# ESP32 register map
Vendor: ESPRESSIF SYSTEMS (SHANGHAI) CO., LTD.; Series: ESP32 Series; File version: 17
CPU: Xtensa LX6 r0p0, little endian, no MPU, FPU, 0 interrupt priority bits
Address unit: 32 bits
Registers are 32-bit, read-write, reset 0x0 unless marked. A register's access mark holds for its fields unless they carry their own. Offsets are from the block's base; [hi:lo] are bit positions; lines under a group give offsets from that group; {n}, {i} and the like mark numbered series; 'fields as' and 'values as' point back to an identical list.

## FLASH_ENCRYPTION — FLASH_ENCRYPTION Peripheral
Base 0x3FF46000
{0x0+4i} BUFFER_{i} (i=0..7) wo
  [7:0] BUFFER — Data buffers for encryption.
0x20 START wo
  [7:0] FLASH_START — Set this bit to start encryption operation on data buffer.
0x24 ADDRESS wo
  [7:0] ADDRESS — The physical address on the off-chip flash must be 8-word boundary aligned.
0x28 DONE ro
  [0] FLASH_DONE — Set this bit when encryption operation is complete.

## FRC_TIMER — FRC_TIMER Peripheral
Base 0x3FF47000
0x00 TIMER_LOAD
  [7:0] VALUE
0x04 TIMER_COUNT
  [7:0] TIMER_COUNT
0x08 TIMER_CTRL
  [8:1] TIMER_PRESCALER
0x0C TIMER_INT
  [0] CLR
0x10 TIMER_ALARM
  [7:0] TIMER_ALARM

## GPIO_SD — Sigma-Delta Modulation
Base 0x3FF44F00
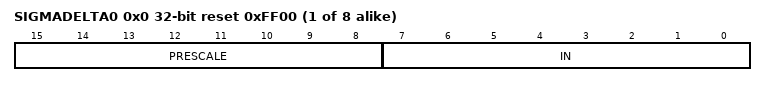
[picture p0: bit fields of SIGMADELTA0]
{0x0+4i} SIGMADELTA{i} (i=0..7) reset 0xFF00
  [15:8] PRESCALE, [7:0] IN
0x20 CLOCK_GATE
  [31] CLK_EN
0x24 SIGMADELTA_MISC
  [31] SPI_SWAP
0x28 VERSION

## HINF — HINF Peripheral
Base 0x3FF4B000
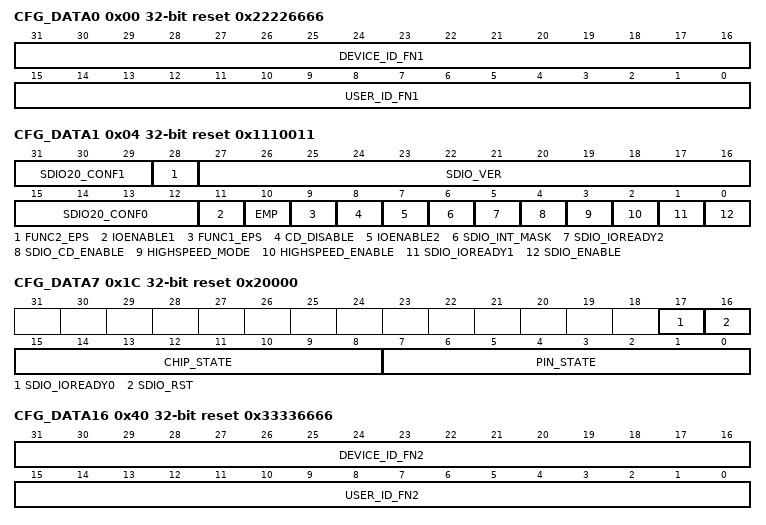
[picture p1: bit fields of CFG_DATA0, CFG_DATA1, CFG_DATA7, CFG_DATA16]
0x00 CFG_DATA0 reset 0x22226666
  [31:16] DEVICE_ID_FN1, [15:0] USER_ID_FN1
0x04 CFG_DATA1 access per field reset 0x1110011
  [31:29] SDIO20_CONF1 rw, [28] FUNC2_EPS ro, [27:16] SDIO_VER rw, [15:12] SDIO20_CONF0 rw, [11] IOENABLE1 ro, [10] EMP ro, [9] FUNC1_EPS ro, [8] CD_DISABLE ro, [7] IOENABLE2 ro, [6] SDIO_INT_MASK rw, [5] SDIO_IOREADY2 rw, [4] SDIO_CD_ENABLE rw, [3] HIGHSPEED_MODE ro, [2] HIGHSPEED_ENABLE rw, [1] SDIO_IOREADY1 rw, [0] SDIO_ENABLE rw
0x1C CFG_DATA7 reset 0x20000
  [17] SDIO_IOREADY0, [16] SDIO_RST, [15:8] CHIP_STATE, [7:0] PIN_STATE
{0x20+4i} CIS_CONF{i} reset 0xFFFFFFFF (i=0..7)
  [31:0] CIS_CONF_W{i}
0x40 CFG_DATA16 reset 0x33336666
  [31:16] DEVICE_ID_FN2, [15:0] USER_ID_FN2
0xFC DATE

## NRX — NRX Peripheral
Base 0x3FF5CC00
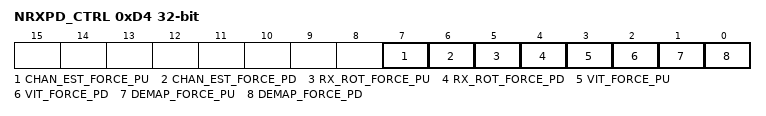
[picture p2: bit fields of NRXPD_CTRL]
0xD4 NRXPD_CTRL — WiFi RX control register
  [7] CHAN_EST_FORCE_PU, [6] CHAN_EST_FORCE_PD, [5] RX_ROT_FORCE_PU, [4] RX_ROT_FORCE_PD, [3] VIT_FORCE_PU, [2] VIT_FORCE_PD, [1] DEMAP_FORCE_PU, [0] DEMAP_FORCE_PD

## PCNT — Pulse Count Controller
Base 0x3FF57000
{0x0+0xC*i} UNIT{i} (i=0..7) group — Cluster UNIT{i}, containing U?_CONF0, U?_CONF1, U?_CONF2
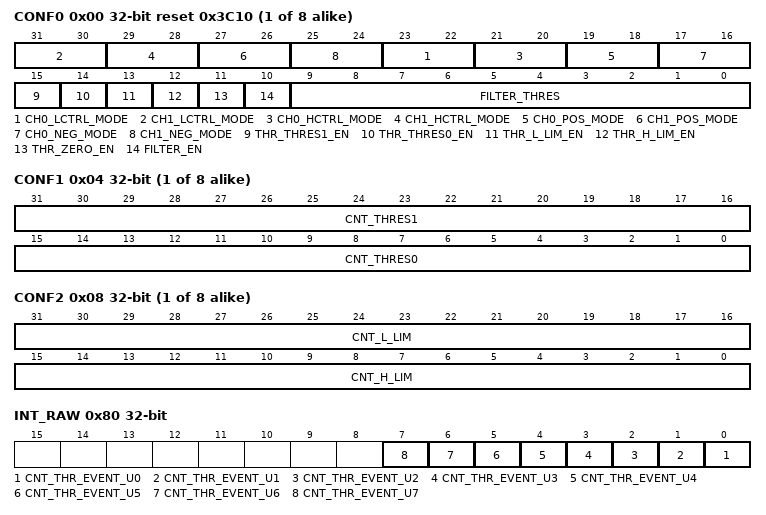
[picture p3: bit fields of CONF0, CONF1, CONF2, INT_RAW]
  0x00 CONF0 reset 0x3C10 — Configuration register 0 for unit
    [8n+23:8n+22] CH{n}_LCTRL_MODE (n=0..1) — Configures how the CHn_POS_MODE/CHn_NEG_MODE settings will be modified when the control signal is low.
      0=Keep (No modification); 1=Reverse (Invert behavior (increase -> decrease); other=Disable (Inhibit counter modification)
    [8n+21:8n+20] CH{n}_HCTRL_MODE (n=0..1) — Configures how the CHn_POS_MODE/CHn_NEG_MODE settings will be modified when the control signal is high.
      values as CH0_LCTRL_MODE
    [8n+19:8n+18] CH{n}_POS_MODE (n=0..1) — Configures the behavior when the signal input of channel {n} detects a positive edge.
      1=Increment (Increase the counter); 2=Decrement (Decrease the counter); other=Hold (No effect on counter)
    [8n+17:8n+16] CH{n}_NEG_MODE (n=0..1) — Configures the behavior when the signal input of channel {n} detects a negative edge.
      values as CH0_POS_MODE
    [15] THR_THRES1_EN — This is the enable bit for comparing unit0's count with thres1 value .
    [14] THR_THRES0_EN — This is the enable bit for comparing unit0's count with thres0 value.
    [13] THR_L_LIM_EN — This is the enable bit for comparing unit0's count with thr_l_lim value.
    [12] THR_H_LIM_EN — This is the enable bit for comparing unit0's count with thr_h_lim value.
    [11] THR_ZERO_EN — This is the enable bit for comparing unit0's count with 0 value.
    [10] FILTER_EN — This is the enable bit for filtering input signals for unit0.
    [9:0] FILTER_THRES — This register is used to filter pluse whose width is smaller than this value for unit0.
  0x04 CONF1
    [31:16] CNT_THRES1 — This register is used to configure thres1 value for unit0.
    [15:0] CNT_THRES0 — This register is used to configure thres0 value for unit0.
  0x08 CONF2
    [31:16] CNT_L_LIM — This register is used to confiugre thr_l_lim value for unit0.
    [15:0] CNT_H_LIM — This register is used to configure thr_h_lim value for unit0.
{0x60+4i} U{i}_CNT (i=0..7) ro
  [15:0] CNT — This register stores the current pulse count value for unit0.
0x80 INT_RAW ro
  [n] CNT_THR_EVENT_U{n} (n=0..7) — This is the interrupt raw bit for channel{n} event.
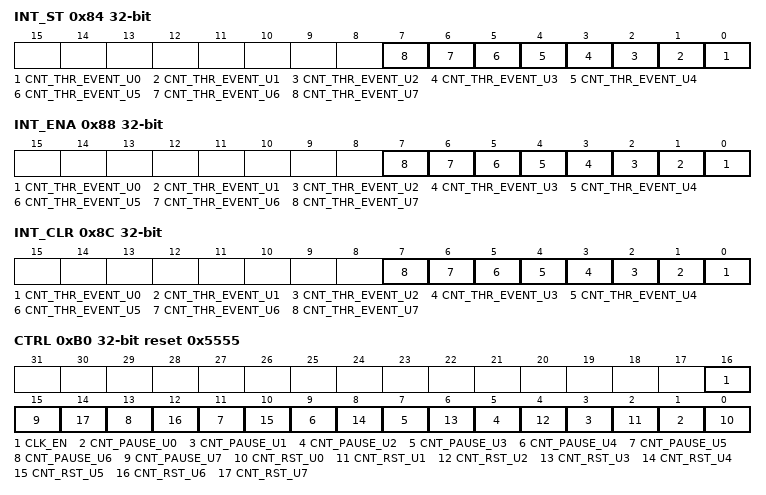
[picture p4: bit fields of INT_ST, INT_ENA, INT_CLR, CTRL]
0x84 INT_ST ro
  [n] CNT_THR_EVENT_U{n} (n=0..7) — This is the interrupt status bit for channel{n} event.
0x88 INT_ENA
  [n] CNT_THR_EVENT_U{n} (n=0..7) — This is the interrupt enable bit for channel{n} event.
0x8C INT_CLR wo
  [n] CNT_THR_EVENT_U{n} (n=0..7) — Set this bit to clear channel{n} event interrupt.
{0x90+4i} U{i}_STATUS (i=0..7) access per field
  [6] ZERO rw, [5] H_LIM rw, [4] L_LIM rw, [3] THRES0 rw, [2] THRES1 rw, [31:0] CORE_STATUS ro, [1:0] ZERO_MODE rw
0xB0 CTRL reset 0x5555
  [16] CLK_EN
  [2n+1] CNT_PAUSE_U{n} (n=0..7) — Set this bit to pause unit{n}'s counter.
  [2n] CNT_RST_U{n} (n=0..7) — Set this bit to clear unit{n}'s counter.
0xFC DATE
